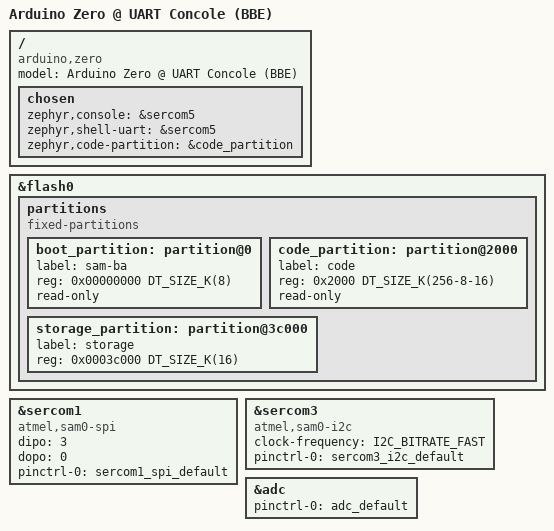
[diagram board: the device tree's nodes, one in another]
/*
 * Copyright (c) 2024-2026 TiaC Systems
 * SPDX-License-Identifier: Apache-2.0
 */

#include "../../zephyr/boards/arduino/zero/arduino_zero.dts"

#include <zephyr/dt-bindings/gpio/gpio.h>
#include <zephyr/dt-bindings/i2c/i2c.h>
#include <mem.h>

#include "arduino_zero-pinctrl.dtsi"
#include "arduino_r3_connector.dtsi"

/ {
	model = "Arduino Zero @ UART Concole (BBE)";
	compatible = "arduino,zero",
		     "arduino,zero-bbe",
		     "arduino,zero-uartcons",
		     "arduino,zero-uartcons-bbe",
		     "atmel,samd21g18a",
		     "atmel,samd21";

	chosen {
		zephyr,console = &sercom5;
		zephyr,shell-uart = &sercom5;
		zephyr,code-partition = &code_partition;
	};
};

&flash0 {
	partitions {
		compatible = "fixed-partitions";
		#address-cells = <1>;
		#size-cells = <1>;

		/* 8 KiB for UF2/BOSSA bootloader */
		boot_partition: partition@0 {
			label = "sam-ba";
			reg = <0x00000000 DT_SIZE_K(8)>;
			read-only;
		};

		/* 232 KiB for application code */
		code_partition: partition@2000 {
			label = "code";
			reg = <0x2000 DT_SIZE_K(256-8-16)>;
			read-only;
		};

		/*
		 * The final 16 KiB is reserved for data storage.
		 * Storage partition will be used by FCB/LittleFS/NVS
		 * if enabled.
		 */
		storage_partition: partition@3c000 {
			label = "storage";
			reg = <0x0003c000 DT_SIZE_K(16)>;
		};
	};
};

&sercom1 {
	status = "okay";
	compatible = "atmel,sam0-spi";
	dipo = <3>;
	dopo = <0>;
	#address-cells = <1>;
	#size-cells = <0>;

	// either: cs-gpios = <&arduino_header ARDUINO_HEADER_R3_D10 GPIO_ACTIVE_LOW>;
	//     or: cs-gpios = <&porta 18 GPIO_ACTIVE_LOW>;
	//     or: pinctrl-0 = <&sercom1_spi_hwss>;

	pinctrl-0 = <&sercom1_spi_default>;
	pinctrl-names = "default";
};

&sercom3 {
	status = "okay";
	compatible = "atmel,sam0-i2c";
	clock-frequency = <I2C_BITRATE_FAST>;
	#address-cells = <1>;
	#size-cells = <0>;

	pinctrl-0 = <&sercom3_i2c_default>;
	pinctrl-names = "default";
};

&adc {
	status = "okay";

	pinctrl-0 = <&adc_default>;
	pinctrl-names = "default";
};
